# DSS_CM_CORE register map
Vendor: Texas Instruments
Peripheral module from a debugger description file (folder omap5430_ES2_PUBLIC).
Registers are 32-bit, access per field, reset 0x70000 unless marked. A register's access mark holds for its fields unless they carry their own. Offsets are as the file gives them; lines under a group give offsets from that group; [hi:lo] are bit positions; {n}, {i} and the like mark numbered series; 'fields as' and 'values as' point back to an identical list; <NAME> marks a mode.

## DSS_CM_CORE
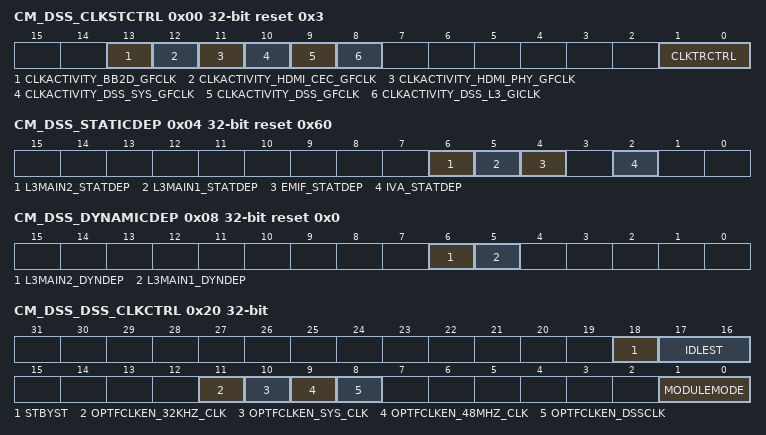
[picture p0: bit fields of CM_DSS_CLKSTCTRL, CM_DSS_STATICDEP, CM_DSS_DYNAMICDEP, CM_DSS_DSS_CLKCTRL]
0x00 CM_DSS_CLKSTCTRL reset 0x3 — This register enables the DSS domain power state transition. It controls the HW supervised domain power state transition between ON-ACTIVE and ON-INACTIVE states. It also holds 1 status bit per clock input of the domain.
  [13] CLKACTIVITY_BB2D_GFCLK ro — This field indicates the state of the BB2D_GFCLK clock in the domain. [warm reset insesitive] Read 0x0: Corresponding clock is definitely gated Read 0x1: Corresponding clock is running or gating/ungating transition is on-going
  [12] CLKACTIVITY_HDMI_CEC_GFCLK ro — This field indicates the state of the HDMI_CEC_GFCLK clock in the domain. [warm reset insensitive] Read 0x0: Corresponding clock is definitely gated Read 0x1: Corresponding clock is running or gating/ungating transition is on-going
  [11] CLKACTIVITY_HDMI_PHY_GFCLK ro — This field indicates the state of the HDMI_PHY_GFCLK clock in the domain. [warm reset insensitive]
    0=Inact (Corresponding clock is definitely gated); 1=Act (Corresponding clock is running or gating/ungating transition is on-going)
  [10] CLKACTIVITY_DSS_SYS_GFCLK ro — This field indicates the state of the DSS_SYS_GFCLK clock in the domain. [warm reset insensitive]
    values as CLKACTIVITY_HDMI_PHY_GFCLK
  [9] CLKACTIVITY_DSS_GFCLK ro — This field indicates the state of the DSS_GFCLK clock in the domain. [warm reset insensitive]
    values as CLKACTIVITY_HDMI_PHY_GFCLK
  [8] CLKACTIVITY_DSS_L3_GICLK ro — This field indicates the state of the DSS_L3_GICLK clock in the domain. [warm reset insensitive]
    values as CLKACTIVITY_HDMI_PHY_GFCLK
  [1:0] CLKTRCTRL rw — Controls the clock state transition of the DSS clock domain.
    0=NO_SLEEP (NO_SLEEP: Sleep transition cannot be initiated. Wakeup transition may however occur.); 1=SW_SLEEP (SW_SLEEP: Start a software forced sleep transition on the domain.); 2=SW_WKUP (SW_WKUP: Start a software forced wake-up transition on the domain.); 3=HW_AUTO (HW_AUTO: Automatic transition is enabled. Sleep and wakeup transition are based upon hardware conditions.)
0x04 CM_DSS_STATICDEP access not given reset 0x60 — This register controls the static domain depedencies from DSS domain towards 'target' domains. It is relevant only for domain having system initiator(s).
  [6] L3MAIN2_STATDEP rw — Static dependency towards L3_MAIN2 clock domain
    0=Disabled (Dependency is disabled); 1=Disabled (Dependency is enabled)
  [5] L3MAIN1_STATDEP — Static dependency towards L3_MAIN1 clock domain (access R Returns 1s)
    1=Enabled (Dependency is enabled)
  [4] EMIF_STATDEP rw — Static dependency towards EMIF clock domain
    0=Disabled (Dependency is disabled); 1=Enabled (Dependency is enabled)
  [2] IVA_STATDEP rw — Static dependency towards IVA clock domain
    values as EMIF_STATDEP
0x08 CM_DSS_DYNAMICDEP ro reset 0x0 — This register controls the dynamic domain depedencies from DSS domain towards 'target' domains. It is relevant only for domain having INTRCONN master port(s).
  [6] L3MAIN2_DYNDEP — Dynamic dependency towards L3_MAIN2 domain
    0=Disabled (Dependency is disabled)
  [5] L3MAIN1_DYNDEP — Dynamic dependency towards L3_MAIN1 domain
    0=Disabled (Dependency is disabled)
0x20 CM_DSS_DSS_CLKCTRL — This register manages the DSS clocks.
  [18] STBYST ro — Module standby status. [warm reset insensitive]
    0=Func (Module is functional (not in standby)); 1=Standby (Module is in standby)
  [17:16] IDLEST ro — Module idle status. [warm reset insensitive]
    0=Func (Module is fully functional, including INTRCONN); 1=Trans (Module is performing transition: wakeup, or sleep, or sleep abortion); 2=Idle (Module is in Idle mode (only INTRCONN part). It is functional if using separate functional clock); 3=Disable (Module is disabled and cannot be accessed)
  [11] OPTFCLKEN_32KHZ_CLK rw — Optional functional clock control.
    0=FCLK_DIS (Optional functional clock is disabled); 1=FCLK_EN (Optional functional clock is enabled)
  [10] OPTFCLKEN_SYS_CLK rw — Optional functional clock control.
    values as OPTFCLKEN_32KHZ_CLK
  [9] OPTFCLKEN_48MHZ_CLK rw — Optional functional clock control.
    values as OPTFCLKEN_32KHZ_CLK
  [8] OPTFCLKEN_DSSCLK rw — Optional functional clock control.
    values as OPTFCLKEN_32KHZ_CLK
  [1:0] MODULEMODE rw — Control the way mandatory clocks are managed.
    0=DISABLED (Module is disable by SW. Any INTRCONN access to module results in an error, except if resulting from a module wakeup (asynchronous wakeup).); 2=ENABLED (Module is explicitly enabled. Interface clock (if not used for functions) may be gated according to the clock domain state. Functional clocks are guarantied to stay present. As long as in this configuration, power domain sleep transition cannot happen.)
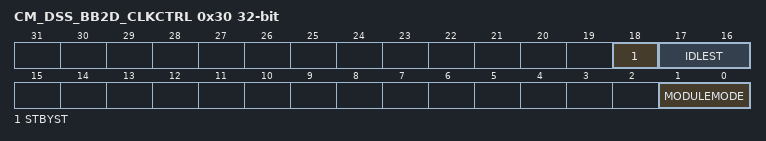
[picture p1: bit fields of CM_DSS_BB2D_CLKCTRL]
0x30 CM_DSS_BB2D_CLKCTRL — This register manages the DSS clocks.
  [18] STBYST ro — Module standby status. [warm reset insensitive]
    values as CM_DSS_DSS_CLKCTRL.STBYST
  [17:16] IDLEST ro — Module idle status. [warm reset insensitive]
    values as CM_DSS_DSS_CLKCTRL.IDLEST
  [1:0] MODULEMODE rw — Control the way mandatory clocks are managed.
    values as CM_DSS_DSS_CLKCTRL.MODULEMODE
